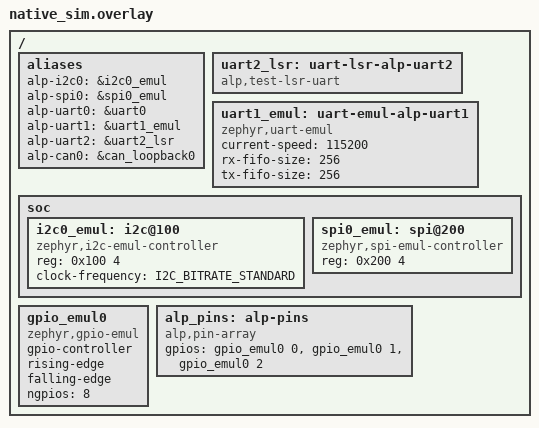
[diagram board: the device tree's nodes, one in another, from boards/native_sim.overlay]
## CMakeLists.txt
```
# SPDX-License-Identifier: Apache-2.0

cmake_minimum_required(VERSION 3.20)

find_package(Zephyr REQUIRED HINTS $ENV{ZEPHYR_BASE})
project(alp_sdk_peripheral_test LANGUAGES C)

# Per-peripheral split landed in §C.16.  main.c keeps the ZTEST_SUITE
# declaration plus the cross-cutting tests (TMU / power / AEN audit
# surfaces / delay / SoC caps / V2N supervisor / TRNG entropy); every
# *.c sibling here registers its ZTESTs against the same suite.
target_sources(app PRIVATE
    src/main.c
    src/config_defaults.c
    src/i2c.c
    src/i2c_target.c
    src/i3c.c
    src/spi.c
    src/spi_target.c
    src/gpio.c
    src/uart.c
    src/lsr_uart.c
    src/pwm.c
    src/adc.c
    src/dac.c
    src/counter.c
    src/qenc.c
    src/i2s.c
    src/can.c
    src/rtc.c
    src/wdt.c
    src/jpeg_bounds.c
)
```

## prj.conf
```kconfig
# SPDX-License-Identifier: Apache-2.0

CONFIG_ZTEST=y
CONFIG_ALP_SDK=y

# Zephyr subsystems we wrap
CONFIG_GPIO=y
CONFIG_I2C=y
CONFIG_SPI=y
CONFIG_SERIAL=y

# v0.2 peripheral subsystems — needed so the wrapper sources compile
# and the alp_*_open NULL/INVAL/last_error paths can be exercised.
# No corresponding controllers in the overlay; alp_*_open returns
# NULL with a precise last_error code.
CONFIG_ADC=y
CONFIG_PWM=y
CONFIG_COUNTER=y
CONFIG_SENSOR=y
CONFIG_I2S=y
CONFIG_CAN=y
CONFIG_RTC=y
CONFIG_WATCHDOG=y
# Required for thread-local last-error storage.
CONFIG_THREAD_LOCAL_STORAGE=y

# peripheral_i2s.c calls k_malloc to allocate its DMA slab; without
# a heap pool the linker rejects the reference.  4 KiB is enough
# for the test's open-with-NULL paths -- real apps that exercise
# alp_i2s_write set this higher.
CONFIG_HEAP_MEM_POOL_SIZE=4096

# Emulated controllers — let the test run under native_sim.
CONFIG_EMUL=y
CONFIG_GPIO_EMUL=y
CONFIG_I2C_EMUL=y
CONFIG_SPI_EMUL=y
# #626: alp-uart1 (RX byte injection for the timeout_ms contract tests
# in src/uart.c) is backed by zephyr,uart-emul, not a real controller.
CONFIG_UART_EMUL=y

CONFIG_LOG=y

# I2C target (slave) mode: compiles the emulated controller's
# target-register hooks so the alp_i2c_target_* lifecycle tests can
# run the open/close roundtrip (nothing external ever drives the
# emulated bus, so callbacks never fire).
CONFIG_I2C_TARGET=y

# SPI target (slave) mode: compiles the SPI drivers' slave path so
# alp_spi_target_open can claim the emulated bus.  CONFIG_SPI_ASYNC
# stays OFF here on purpose -- the spi_target tests pin down the
# documented degrade: a finite transceive timeout on a sync-only
# build must fail with ALP_ERR_NOSUPPORT instead of blocking.
CONFIG_SPI_SLAVE=y
```

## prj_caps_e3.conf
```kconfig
# SPDX-License-Identifier: Apache-2.0
#
# Overlay onto prj.conf for the alp_sdk.peripheral.caps_e3 scenario.
# Pins the SoC choice to Alif Ensemble E3 so the capability-validation
# tests in main.c can verify *_open rejects configs that exceed the
# E3's documented hardware caps.

CONFIG_ALP_SOC_ALIF_ENSEMBLE_E3=y
```

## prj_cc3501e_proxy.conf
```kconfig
# SPDX-License-Identifier: Apache-2.0
#
# Turns on the CC3501E GPIO proxy so src/gpio_proxy.c's delegated-path
# test (issue #1618) compiles and runs.  The proxy registers at priority
# 200, above the platform gpio backend's 100, so alp_gpio_open() goes
# through px_open here.  With the shipped weak-EMPTY cc3501e_gpio_routes[]
# table and no alp_gpio_cc3501e_attach() call, EVERY pin takes the
# delegated path -- which is the path under test.
#
# Kept out of prj.conf on purpose: enabling the proxy for every scenario
# in this directory would route every existing GPIO test through it.
CONFIG_ALP_SDK_CHIP_CC3501E=y
CONFIG_ALP_SDK_GPIO_CC3501E_PROXY=y
```

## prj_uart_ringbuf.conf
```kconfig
# SPDX-License-Identifier: Apache-2.0
# Twister overlay that flips CONFIG_ALP_SDK_UART_RX_RINGBUF on so the
# interrupt-driven RX ring buffer code path in peripheral_uart.c is
# compile-tested alongside its NOSUPPORT siblings.  Real-IRQ attach
# requires a working UART driver (HIL) so the failure-path tests
# here verify NULL-arg handling only.

CONFIG_UART_INTERRUPT_DRIVEN=y
CONFIG_ALP_SDK_UART_RX_RINGBUF=y
```

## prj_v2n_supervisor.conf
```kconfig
# SPDX-License-Identifier: Apache-2.0
#
# Overlay onto prj.conf for the alp_sdk.peripheral.v2n_supervisor
# scenario.  Force-enables the V2N SoC choice + GD32G553 chip driver
# + the supervisor singleton so the bridge dispatcher branches in
# peripheral_pwm.c / _adc.c / _qenc.c / _counter.c / _dac.c get
# compiled and the open() paths surface ALP_ERR_NOT_READY from the
# supervisor (no bus IDs configured -> no actual GD32 link).
#
# This scenario does NOT exercise the GD32 firmware -- native_sim
# has no SPI/I2C controller wired to a GD32 emul.  The intent is to
# prove that the V2N branch compiles + routes correctly back to the
# portable surface; real-silicon round-trip coverage lives in the
# v2n HIL test plan.

CONFIG_ALP_SOC_RENESAS_RZV2N_N44=y
CONFIG_ALP_SDK_CHIP_GD32G553=y
CONFIG_ALP_SDK_V2N_SUPERVISOR=y
# ALP_ADC_HAS_FILTER_PATH (src/zephyr/peripheral_adc.c) needs BOTH
# CONFIG_ALP_SDK_DSP and the V2N bridge path -- without this, the
# alp_adc_filter_*/alp_adc_spectrum_* bodies above are never compiled
# by any gate in the tree (issue #1634 dev-review follow-up).
CONFIG_ALP_SDK_DSP=y
```

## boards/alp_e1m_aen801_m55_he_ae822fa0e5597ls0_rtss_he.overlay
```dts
/*
 * Copyright 2026 Alp Lab AB
 * SPDX-License-Identifier: Apache-2.0
 *
 * Overlay for running the Alp SDK peripheral ztest on the
 * E1M EVK (UG-E1M-001) populated with an E1M-AEN family SoM.
 *
 * Wires the studio-resolved peripheral aliases to the EVK
 * connectors: I2C0 to the on-board sensor bus, SPI0 to the M.2
 * Key M slot, UART0 to the JTAG/SWD header's serial side, and the
 * alp,pin-array to the rotary encoder + RGB LED + IO-expander
 * control pins.
 *
 * The alp,pin-array is POSITIONAL: alp_z_gpio_resolve(pin_id)
 * indexes it by the E1M GPIO index, so entry N is E1M pad N in the
 * e1m_pinout.h canonical order (IO0..IO25 = 0..25, PWM0..PWM7 =
 * 26..33, ...).  The EVK's RGB LED sits on PWM pads, so it is
 * driven through the pads' GPIO-secondary indices (ALP_E1M_GPIO_PWM*);
 * this overlay covers indices 0..29.
 *
 * The alp_e1m_aen801_m55_he board file itself ships in-tree at
 * zephyr/boards/alp/e1m_aen801_m55_he/; this overlay only re-aliases
 * what that board exposes.
 */

#include <zephyr/dt-bindings/gpio/gpio.h>

/ {
    aliases {
        alp-i2c0  = &i2c0;       /* sensor bus on the EVK (ICM-42670-P, BMI323, BMP581, TCAL9538) */
        alp-spi0  = &spi0;       /* routed to the M.2 Key M slot for off-board flash */
        alp-uart0 = &uart0;      /* console / JTAG-side debug uart */
    };

    /* Positional alp,pin-array (e1m_pinout.h canonical order).  Only
     * the indices the EVK routes carry a meaningful net; the rest are
     * placeholders so the positional index stays stable.  The gpio
     * bank/pin numbers are PLACEHOLDERS (see NOTE below).  */
    alp_pins: alp-pins {
        compatible = "alp,pin-array";
        gpios = <&gpio0  0 GPIO_ACTIVE_HIGH>,                            /* [ 0] ALP_E1M_GPIO_IO0  (unrouted placeholder) */
                <&gpio0  1 GPIO_ACTIVE_HIGH>,                            /* [ 1] ALP_E1M_GPIO_IO1  (unrouted placeholder) */
                <&gpio0  2 GPIO_ACTIVE_HIGH>,                            /* [ 2] ALP_E1M_GPIO_IO2  (unrouted placeholder) */
                <&gpio0  3 GPIO_ACTIVE_HIGH>,                            /* [ 3] ALP_E1M_GPIO_IO3  (unrouted placeholder) */
                <&gpio1  0 (GPIO_ACTIVE_HIGH | GPIO_PULL_UP)>,           /* [ 4] ALP_E1M_GPIO_IO4  -- EVK_PIN_ENCODER_SW */
                <&gpio0  5 GPIO_ACTIVE_HIGH>,                            /* [ 5] ALP_E1M_GPIO_IO5  (unrouted placeholder) */
                <&gpio0  6 GPIO_ACTIVE_HIGH>,                            /* [ 6] ALP_E1M_GPIO_IO6  (unrouted placeholder) */
                <&gpio1  1 GPIO_ACTIVE_HIGH>,                            /* [ 7] ALP_E1M_GPIO_IO7  -- EVK_PIN_PCIE_IOEXP_INT */
                <&gpio0  8 GPIO_ACTIVE_HIGH>,                            /* [ 8] ALP_E1M_GPIO_IO8  (unrouted placeholder) */
                <&gpio1  2 GPIO_ACTIVE_HIGH>,                            /* [ 9] ALP_E1M_GPIO_IO9  -- EVK_PIN_PCIE_IOEXP_RST */
                <&gpio0 10 GPIO_ACTIVE_HIGH>,                            /* [10] ALP_E1M_GPIO_IO10 (unrouted placeholder) */
                <&gpio0 11 GPIO_ACTIVE_HIGH>,                            /* [11] ALP_E1M_GPIO_IO11 (unrouted placeholder) */
                <&gpio0 12 GPIO_ACTIVE_HIGH>,                            /* [12] ALP_E1M_GPIO_IO12 (unrouted placeholder) */
                <&gpio0 13 GPIO_ACTIVE_HIGH>,                            /* [13] ALP_E1M_GPIO_IO13 (unrouted placeholder) */
                <&gpio0 14 GPIO_ACTIVE_HIGH>,                            /* [14] ALP_E1M_GPIO_IO14 (unrouted placeholder) */
                <&gpio0 15 GPIO_ACTIVE_HIGH>,                            /* [15] ALP_E1M_GPIO_IO15 (unrouted placeholder) */
                <&gpio0 16 GPIO_ACTIVE_HIGH>,                            /* [16] ALP_E1M_GPIO_IO16 (unrouted placeholder) */
                <&gpio0 17 GPIO_ACTIVE_HIGH>,                            /* [17] ALP_E1M_GPIO_IO17 (unrouted placeholder) */
                <&gpio0 18 GPIO_ACTIVE_HIGH>,                            /* [18] ALP_E1M_GPIO_IO18 (unrouted placeholder) */
                <&gpio0 19 GPIO_ACTIVE_HIGH>,                            /* [19] ALP_E1M_GPIO_IO19 (unrouted placeholder) */
                <&gpio0 20 GPIO_ACTIVE_HIGH>,                            /* [20] ALP_E1M_GPIO_IO20 (unrouted placeholder) */
                <&gpio0 21 GPIO_ACTIVE_HIGH>,                            /* [21] ALP_E1M_GPIO_IO21 (unrouted placeholder) */
                <&gpio0 22 GPIO_ACTIVE_HIGH>,                            /* [22] ALP_E1M_GPIO_IO22 (unrouted placeholder) */
                <&gpio0 23 GPIO_ACTIVE_HIGH>,                            /* [23] ALP_E1M_GPIO_IO23 (unrouted placeholder) */
                <&gpio0 24 GPIO_ACTIVE_HIGH>,                            /* [24] ALP_E1M_GPIO_IO24 (unrouted placeholder) */
                <&gpio0 25 GPIO_ACTIVE_HIGH>,                            /* [25] ALP_E1M_GPIO_IO25 (unrouted placeholder) */
                <&gpio0 26 GPIO_ACTIVE_HIGH>,                            /* [26] ALP_E1M_GPIO_PWM0 -- EVK_PWM_LED_GREEN as GPIO */
                <&gpio0 27 GPIO_ACTIVE_HIGH>,                            /* [27] ALP_E1M_GPIO_PWM1 -- EVK_PWM_LED_BLUE as GPIO */
                <&gpio0 28 GPIO_ACTIVE_HIGH>,                            /* [28] ALP_E1M_GPIO_PWM2 (unrouted placeholder) */
                <&gpio0 29 GPIO_ACTIVE_HIGH>;                            /* [29] ALP_E1M_GPIO_PWM3 -- EVK_PWM_LED_RED as GPIO */
    };
};

/*
 * NOTE — gpio bank/pin numbers in the gpios property above are
 * PLACEHOLDERS.  The authoritative mapping lands when the
 * alp_e1m_aen801_m55_he board file (zephyr/boards/alp/e1m_aen801_m55_he/)
 * grows a pinctrl group naming the exact gpio bank/index for each
 * EVK net (RGB LED on the PWM pads, encoder switch, IO_EXP.INT/RST).
 * The POSITIONAL INDEX (the [NN] in each comment) is the stable ABI;
 * only the <&gpioX Y> columns are TBD.
 */
```

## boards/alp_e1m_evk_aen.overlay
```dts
/*
 * Copyright 2026 Alp Lab AB
 * SPDX-License-Identifier: Apache-2.0
 *
 * Overlay for running the Alp SDK peripheral ztest on the
 * E1M EVK (UG-E1M-001) populated with an E1M-AEN family SoM.
 *
 * Wires the studio-resolved peripheral aliases to the EVK
 * connectors: I2C0 to the on-board sensor bus, SPI0 to the M.2
 * Key M slot, UART0 to the JTAG/SWD header's serial side, and the
 * alp,pin-array to the rotary encoder + RGB LED + IO-expander
 * control pins.
 *
 * The alp,pin-array is POSITIONAL: alp_z_gpio_resolve(pin_id)
 * indexes it by the E1M GPIO index, so entry N is E1M pad N in the
 * e1m_pinout.h canonical order (IO0..IO25 = 0..25, PWM0..PWM7 =
 * 26..33, ...).  The EVK's RGB LED sits on PWM pads, so it is
 * driven through the pads' GPIO-secondary indices (ALP_E1M_GPIO_PWM*);
 * this overlay covers indices 0..29.
 *
 * The alp_e1m_evk_aen board file itself lives in
 * alplabai/alp-zephyr-modules; this overlay only re-aliases what
 * that board exposes.
 */

#include <zephyr/dt-bindings/gpio/gpio.h>

/ {
    aliases {
        alp-i2c0  = &i2c0;       /* sensor bus on the EVK (ICM-42670-P, BMI323, BMP581, TCAL9538) */
        alp-spi0  = &spi0;       /* routed to the M.2 Key M slot for off-board flash */
        alp-uart0 = &uart0;      /* console / JTAG-side debug uart */
    };

    /* Positional alp,pin-array (e1m_pinout.h canonical order).  Only
     * the indices the EVK routes carry a meaningful net; the rest are
     * placeholders so the positional index stays stable.  The gpio
     * bank/pin numbers are PLACEHOLDERS (see NOTE below).  */
    alp_pins: alp-pins {
        compatible = "alp,pin-array";
        gpios = <&gpio0  0 GPIO_ACTIVE_HIGH>,                            /* [ 0] ALP_E1M_GPIO_IO0  (unrouted placeholder) */
                <&gpio0  1 GPIO_ACTIVE_HIGH>,                            /* [ 1] ALP_E1M_GPIO_IO1  (unrouted placeholder) */
                <&gpio0  2 GPIO_ACTIVE_HIGH>,                            /* [ 2] ALP_E1M_GPIO_IO2  (unrouted placeholder) */
                <&gpio0  3 GPIO_ACTIVE_HIGH>,                            /* [ 3] ALP_E1M_GPIO_IO3  (unrouted placeholder) */
                <&gpio1  0 (GPIO_ACTIVE_HIGH | GPIO_PULL_UP)>,           /* [ 4] ALP_E1M_GPIO_IO4  -- EVK_PIN_ENCODER_SW */
                <&gpio0  5 GPIO_ACTIVE_HIGH>,                            /* [ 5] ALP_E1M_GPIO_IO5  (unrouted placeholder) */
                <&gpio0  6 GPIO_ACTIVE_HIGH>,                            /* [ 6] ALP_E1M_GPIO_IO6  (unrouted placeholder) */
                <&gpio1  1 GPIO_ACTIVE_HIGH>,                            /* [ 7] ALP_E1M_GPIO_IO7  -- EVK_PIN_PCIE_IOEXP_INT */
                <&gpio0  8 GPIO_ACTIVE_HIGH>,                            /* [ 8] ALP_E1M_GPIO_IO8  (unrouted placeholder) */
                <&gpio1  2 GPIO_ACTIVE_HIGH>,                            /* [ 9] ALP_E1M_GPIO_IO9  -- EVK_PIN_PCIE_IOEXP_RST */
                <&gpio0 10 GPIO_ACTIVE_HIGH>,                            /* [10] ALP_E1M_GPIO_IO10 (unrouted placeholder) */
                <&gpio0 11 GPIO_ACTIVE_HIGH>,                            /* [11] ALP_E1M_GPIO_IO11 (unrouted placeholder) */
                <&gpio0 12 GPIO_ACTIVE_HIGH>,                            /* [12] ALP_E1M_GPIO_IO12 (unrouted placeholder) */
                <&gpio0 13 GPIO_ACTIVE_HIGH>,                            /* [13] ALP_E1M_GPIO_IO13 (unrouted placeholder) */
                <&gpio0 14 GPIO_ACTIVE_HIGH>,                            /* [14] ALP_E1M_GPIO_IO14 (unrouted placeholder) */
                <&gpio0 15 GPIO_ACTIVE_HIGH>,                            /* [15] ALP_E1M_GPIO_IO15 (unrouted placeholder) */
                <&gpio0 16 GPIO_ACTIVE_HIGH>,                            /* [16] ALP_E1M_GPIO_IO16 (unrouted placeholder) */
                <&gpio0 17 GPIO_ACTIVE_HIGH>,                            /* [17] ALP_E1M_GPIO_IO17 (unrouted placeholder) */
                <&gpio0 18 GPIO_ACTIVE_HIGH>,                            /* [18] ALP_E1M_GPIO_IO18 (unrouted placeholder) */
                <&gpio0 19 GPIO_ACTIVE_HIGH>,                            /* [19] ALP_E1M_GPIO_IO19 (unrouted placeholder) */
                <&gpio0 20 GPIO_ACTIVE_HIGH>,                            /* [20] ALP_E1M_GPIO_IO20 (unrouted placeholder) */
                <&gpio0 21 GPIO_ACTIVE_HIGH>,                            /* [21] ALP_E1M_GPIO_IO21 (unrouted placeholder) */
                <&gpio0 22 GPIO_ACTIVE_HIGH>,                            /* [22] ALP_E1M_GPIO_IO22 (unrouted placeholder) */
                <&gpio0 23 GPIO_ACTIVE_HIGH>,                            /* [23] ALP_E1M_GPIO_IO23 (unrouted placeholder) */
                <&gpio0 24 GPIO_ACTIVE_HIGH>,                            /* [24] ALP_E1M_GPIO_IO24 (unrouted placeholder) */
                <&gpio0 25 GPIO_ACTIVE_HIGH>,                            /* [25] ALP_E1M_GPIO_IO25 (unrouted placeholder) */
                <&gpio0 26 GPIO_ACTIVE_HIGH>,                            /* [26] ALP_E1M_GPIO_PWM0 -- EVK_PWM_LED_GREEN as GPIO */
                <&gpio0 27 GPIO_ACTIVE_HIGH>,                            /* [27] ALP_E1M_GPIO_PWM1 -- EVK_PWM_LED_BLUE as GPIO */
                <&gpio0 28 GPIO_ACTIVE_HIGH>,                            /* [28] ALP_E1M_GPIO_PWM2 (unrouted placeholder) */
                <&gpio0 29 GPIO_ACTIVE_HIGH>;                            /* [29] ALP_E1M_GPIO_PWM3 -- EVK_PWM_LED_RED as GPIO */
    };
};

/*
 * NOTE — gpio bank/pin numbers in the gpios property above are
 * PLACEHOLDERS.  The authoritative mapping lands when
 * alplabai/alp-zephyr-modules publishes the alp_e1m_evk_aen board
 * file with a pinctrl group naming the exact gpio bank/index for each
 * EVK net (RGB LED on the PWM pads, encoder switch, IO_EXP.INT/RST).
 * The POSITIONAL INDEX (the [NN] in each comment) is the stable ABI;
 * only the <&gpioX Y> columns are TBD.
 */
```

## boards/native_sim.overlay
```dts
/*
 * Copyright 2026 Alp Lab AB
 * SPDX-License-Identifier: Apache-2.0
 *
 * Devicetree overlay for the alp-sdk peripheral ztest under
 * native_sim.  Wires three emulated GPIOs, one emulated I2C bus,
 * one emulated SPI bus, the existing native_sim UART (uart0), and
 * one emulated UART (uart-emul) to the alias names alp_sdk's Zephyr
 * backend looks up.
 */

#include <zephyr/dt-bindings/gpio/gpio.h>

/ {
    aliases {
        alp-i2c0  = &i2c0_emul;
        alp-spi0  = &spi0_emul;
        alp-uart0 = &uart0;
        alp-uart1 = &uart1_emul;
        alp-uart2 = &uart2_lsr;
        /* #1631: alp-can0 -> the board's own can_loopback0 (status
         * "okay" by default in native_sim.dts) so the CAN backend's
         * z_send() bound-check test in
         * tests/zephyr/peripheral/src/can.c opens a REAL Zephyr CAN
         * device instead of the NULL that ALP_CAN_DEV_OR_NULL()
         * yields (src/backends/can/zephyr_drv.c) when the alias is
         * unset. */
        alp-can0  = &can_loopback0;
    };

    /* #626: alp_uart_read()'s timeout_ms == 0 / finite / partial-fill
     * contract needs bytes we control injecting into RX -- uart0 is
     * native_sim's real backing UART with no test-side RX hook, so a
     * second, purely emulated UART (uart_emul_put_rx_data()) backs
     * the timeout tests in src/uart.c instead of port 0. */
    /* #2934: UART whose poll_in() clears the error latch like ns16550's LSR
     * read (src/lsr_uart.c). */
    uart2_lsr: uart-lsr-alp-uart2 {
        compatible = "alp,test-lsr-uart";
        status = "okay";
    };

    uart1_emul: uart-emul-alp-uart1 {
        compatible = "zephyr,uart-emul";
        status = "okay";
        current-speed = <115200>;
        rx-fifo-size = <256>;
        tx-fifo-size = <256>;
    };

    soc {
        i2c0_emul: i2c@100 {
            compatible = "zephyr,i2c-emul-controller";
            status = "okay";
            reg = <0x100 4>;
            #address-cells = <1>;
            #size-cells = <0>;
            clock-frequency = <I2C_BITRATE_STANDARD>;
        };

        spi0_emul: spi@200 {
            compatible = "zephyr,spi-emul-controller";
            status = "okay";
            reg = <0x200 4>;
            #address-cells = <1>;
            #size-cells = <0>;
        };
    };

    gpio_emul0: gpio_emul0 {
        compatible = "zephyr,gpio-emul";
        status = "okay";
        gpio-controller;
        rising-edge;
        falling-edge;
        #gpio-cells = <2>;
        ngpios = <8>;
    };

    alp_pins: alp-pins {
        compatible = "alp,pin-array";
        gpios = <&gpio_emul0 0 GPIO_ACTIVE_HIGH>,
                <&gpio_emul0 1 GPIO_ACTIVE_HIGH>,
                <&gpio_emul0 2 (GPIO_ACTIVE_HIGH | GPIO_PULL_UP)>;
    };
};
```

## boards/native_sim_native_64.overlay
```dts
/*
 * Copyright 2026 Alp Lab AB
 * SPDX-License-Identifier: Apache-2.0
 *
 * Devicetree overlay for the alp-sdk peripheral ztest under
 * native_sim.  Wires three emulated GPIOs, one emulated I2C bus,
 * one emulated SPI bus, the existing native_sim UART (uart0), and
 * one emulated UART (uart-emul) to the alias names alp_sdk's Zephyr
 * backend looks up.
 */

#include <zephyr/dt-bindings/gpio/gpio.h>
#include <zephyr/dt-bindings/i2c/i2c.h>

/ {
    aliases {
        alp-i2c0  = &i2c0_emul;
        alp-spi0  = &spi0_emul;
        alp-uart0 = &uart0;
        alp-uart1 = &uart1_emul;
        alp-uart2 = &uart2_lsr;
        /* #1631: alp-can0 -> the board's own can_loopback0 (status
         * "okay" by default in native_sim.dts, #include-d by this
         * platform's own native_sim_64.dts) so the CAN backend's
         * z_send() bound-check test in
         * tests/zephyr/peripheral/src/can.c opens a REAL Zephyr CAN
         * device instead of the NULL that ALP_CAN_DEV_OR_NULL()
         * yields (src/backends/can/zephyr_drv.c) when the alias is
         * unset. */
        alp-can0  = &can_loopback0;
    };

    /* #626: alp_uart_read()'s timeout_ms == 0 / finite / partial-fill
     * contract needs bytes we control injecting into RX -- uart0 is
     * native_sim's real backing UART with no test-side RX hook, so a
     * second, purely emulated UART (uart_emul_put_rx_data()) backs
     * the timeout tests in src/uart.c instead of port 0. */
    /* #2934: UART whose poll_in() clears the error latch like ns16550's LSR
     * read (src/lsr_uart.c). */
    uart2_lsr: uart-lsr-alp-uart2 {
        compatible = "alp,test-lsr-uart";
        status = "okay";
    };

    uart1_emul: uart-emul-alp-uart1 {
        compatible = "zephyr,uart-emul";
        status = "okay";
        current-speed = <115200>;
        rx-fifo-size = <256>;
        tx-fifo-size = <256>;
    };

    /* native_sim's /soc has #address-cells=2, #size-cells=1, so
     * `reg` needs three cells: <addr_hi addr_lo size>. */
    soc {
        i2c0_emul: i2c@100 {
            compatible = "zephyr,i2c-emul-controller";
            status = "okay";
            reg = <0 0x100 4>;
            #address-cells = <1>;
            #size-cells = <0>;
            clock-frequency = <I2C_BITRATE_STANDARD>;
        };

        spi0_emul: spi@200 {
            compatible = "zephyr,spi-emul-controller";
            status = "okay";
            reg = <0 0x200 4>;
            #address-cells = <1>;
            #size-cells = <0>;
        };
    };

    gpio_emul0: gpio_emul0 {
        compatible = "zephyr,gpio-emul";
        status = "okay";
        gpio-controller;
        rising-edge;
        falling-edge;
        #gpio-cells = <2>;
        ngpios = <8>;
    };

    alp_pins: alp-pins {
        compatible = "alp,pin-array";
        gpios = <&gpio_emul0 0 GPIO_ACTIVE_HIGH>,
                <&gpio_emul0 1 GPIO_ACTIVE_HIGH>,
                <&gpio_emul0 2 (GPIO_ACTIVE_HIGH | GPIO_PULL_UP)>;
    };
};
```

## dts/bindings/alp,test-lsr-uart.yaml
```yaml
# SPDX-License-Identifier: Apache-2.0
description: |
  Test-only UART whose poll_in() clears the error latch the way ns16550's LSR
  read does (see src/lsr_uart.c).  Not a real controller.

compatible: "alp,test-lsr-uart"

include: base.yaml
```

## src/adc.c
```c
/*
 * Copyright 2026 Alp Lab AB
 * SPDX-License-Identifier: Apache-2.0
 *
 * <alp/adc.h> -- ADC wrapper tests.  Extracted from main.c in §C.16.
 * Covers the basic open NULL+OOB paths and the streaming ADC surface
 * (alp_adc_stream_*).  Default native_sim builds have no streaming
 * backend so streaming open returns NOSUPPORT for valid configs --
 * the NULL-cfg path stays INVAL on every backend.
 */

#include <zephyr/ztest.h>

#include "alp/adc.h"
#include "alp/peripheral.h"

ZTEST(alp_peripheral, test_adc_null_cfg)
{
	zassert_is_null(alp_adc_open(NULL));
	zassert_equal(alp_last_error(), ALP_ERR_INVAL);
}

ZTEST(alp_peripheral, test_adc_unresolved_channel_yields_not_ready)
{
	/* channel_id=0 is in-range; with no `alp-adc0` alias on this
     * test's overlay the spec is NULL → ALP_ERR_NOT_READY. */
	alp_adc_t *a = alp_adc_open(&(alp_adc_config_t){ .channel_id = 0, .resolution_bits = 12 });
	zassert_is_null(a);
#if defined(CONFIG_ALP_SOC_NONE)
	/* With no SoC selected, capability checks pass through and we
     * land on the device-not-ready path. */
	zassert_equal(alp_last_error(), ALP_ERR_NOT_READY);
#endif
}

/* ------------------------------------------------------------------ */
/* Streaming ADC                                                       */
/*                                                                     */
/* Default native_sim builds have no streaming backend (the Zephyr     */
/* adc_* class doesn't expose a portable streaming primitive matching  */
/* alp_adc_stream_*), so open() returns NULL + ALP_ERR_NOSUPPORT for   */
/* any non-NULL config.  The NULL-cfg path returns INVAL regardless,   */
/* and the read/close NULL-arg paths must always be safe.              */
/* ------------------------------------------------------------------ */

ZTEST(alp_peripheral, test_adc_stream_null_cfg)
{
	zassert_is_null(alp_adc_stream_open(NULL));
	zassert_equal(alp_last_error(), ALP_ERR_INVAL);
}

ZTEST(alp_peripheral, test_adc_stream_read_null_handle_yields_not_ready)
{
	uint16_t     buf[4];
	size_t       got = 99u;
	alp_status_t s   = alp_adc_stream_read_mv(NULL, buf, ARRAY_SIZE(buf), &got);
	zassert_equal(s, ALP_ERR_NOT_READY, "got %d", (int)s);
	zassert_equal(got, 0u, "got must be zeroed on failure");
}

ZTEST(alp_peripheral, test_adc_stream_read_null_got_is_inval)
{
	uint16_t     buf[4];
	alp_status_t s = alp_adc_stream_read_mv(NULL, buf, ARRAY_SIZE(buf), NULL);
	zassert_equal(s, ALP_ERR_INVAL, "NULL got pointer must be INVAL, got %d", (int)s);
}

ZTEST(alp_peripheral, test_adc_stream_close_null_safe)
{
	/* Must not crash. */
	alp_adc_stream_close(NULL);
}

#if !defined(CONFIG_ALP_SDK_V2N_SUPERVISOR)
ZTEST(alp_peripheral, test_adc_stream_open_no_backend_yields_nosupport)
{
	/* Default build has no streaming backend.  Any well-formed cfg
     * lands on the NOSUPPORT sentinel; this catches accidental
     * regressions where a future backend silently links in. */
	alp_adc_stream_t *s = alp_adc_stream_open(&(alp_adc_stream_config_t){
	    .channel_id     = 0u,
	    .sample_rate_hz = 100000u,
	});
	zassert_is_null(s);
	zassert_equal(alp_last_error(), ALP_ERR_NOSUPPORT);
}
#endif
```

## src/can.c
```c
/*
 * Copyright 2026 Alp Lab AB
 * SPDX-License-Identifier: Apache-2.0
 *
 * <alp/can.h> -- CAN wrapper tests.  Extracted from main.c in §C.16.
 */

#include <string.h>

#include <zephyr/ztest.h>

#include "alp/can.h"
#include "alp/peripheral.h"

ZTEST(alp_peripheral, test_can_null_cfg)
{
	zassert_is_null(alp_can_open(NULL));
	zassert_equal(alp_last_error(), ALP_ERR_INVAL);
}

ZTEST(alp_peripheral, test_can_zero_bitrate_rejected)
{
	alp_can_t *c = alp_can_open(&(alp_can_config_t){ .bus_id             = 0,
	                                                 .bitrate_nominal_hz = 0, /* INVAL */
	                                                 .mode               = ALP_CAN_MODE_CLASSIC });
	zassert_is_null(c);
	zassert_equal(alp_last_error(), ALP_ERR_INVAL);
}

/* #1631: an fd-flagged, 64-byte frame sent on a handle opened
 * ALP_CAN_MODE_CLASSIC must be rejected cleanly -- src/can_dispatch.c's
 * payload_len bound check alone lets it through (64 is not
 * > ALP_CAN_MAX_PAYLOAD_BYTES_FD, and the classic-payload arm is
 * skipped because frame->fd is true), so without the mode guard this
 * reaches src/backends/can/zephyr_drv.c's z_send(), which memcpy()s
 * frame->payload_len bytes into an on-stack struct can_frame sized by
 * Zephyr's CAN_MAX_DLEN -- 8 bytes on this suite's build (no
 * CONFIG_CAN_FD_MODE) -- a 56-byte stack overflow. */
ZTEST(alp_peripheral, test_can_fd_frame_rejected_on_classic_handle)
{
	alp_can_t *c = alp_can_open(&(alp_can_config_t){
	    .bus_id = 0, .bitrate_nominal_hz = 500000, .mode = ALP_CAN_MODE_CLASSIC });
	zassert_not_null(c, "alp_can_open(0) returned NULL -- is native_sim's alp-can0 alias wired?");
	zassert_equal(alp_can_start(c), ALP_OK, "alp_can_start() failed");

	alp_can_frame_t frame = { 0 };
	frame.id              = 0x123;
	frame.fd              = true;
	frame.payload_len     = ALP_CAN_MAX_PAYLOAD_BYTES_FD; /* 64 */
	memset(frame.data, 0x5A, sizeof(frame.data));

	alp_status_t rc = alp_can_send(c, &frame, 100);
	zassert_equal(rc,
	              ALP_ERR_NOSUPPORT,
	              "fd-flagged 64-byte send on a classic-mode handle returned %d, not "
	              "ALP_ERR_NOSUPPORT from src/can_dispatch.c's mode guard",
	              (int)rc);

	alp_can_close(c);
}
```

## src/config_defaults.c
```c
/*
 * Copyright 2026 Alp Lab AB
 * SPDX-License-Identifier: Apache-2.0
 *
 * ALP_*_CONFIG_DEFAULT(id) contract (#610 WS1): each macro fills the
 * identity field from its argument and every other field with the one
 * canonical default documented in the public header. These tests pin
 * those defaults so a header edit that silently changes a default is
 * caught. They assert VALUES, not hardware behavior -- the macros are
 * header-only, so this runs on native_sim with no backend.
 */

#include <zephyr/ztest.h>

#include "alp/peripheral.h"
#include "alp/pwm.h"
#include "alp/dac.h"
#include "alp/wdt.h"
#include "alp/counter.h"
#include "alp/can.h"
#include "alp/adc.h"
#include "alp/audio.h"
#include "alp/ble.h"
#include "alp/camera.h"
#include "alp/display.h"
#include "alp/i2s.h"
#include "alp/inference.h"
#include "alp/mproc.h"
#include "alp/iot.h"
#include "alp/rpc.h"
#include "alp/storage.h"
#include "alp/usb.h"

ZTEST(alp_peripheral, test_i2c_config_default)
{
	alp_i2c_config_t cfg = ALP_I2C_CONFIG_DEFAULT(5u);
	zassert_equal(cfg.bus_id, 5u, "identity from the macro arg");
	zassert_equal(cfg.bitrate_hz, 100000u, "I2C standard-mode default");
}

ZTEST(alp_peripheral, test_spi_config_default)
{
	alp_spi_config_t cfg = ALP_SPI_CONFIG_DEFAULT(2u);
	zassert_equal(cfg.bus_id, 2u, NULL);
	zassert_equal(cfg.freq_hz, 1000000u, "1 MHz default");
	zassert_equal(cfg.mode, ALP_SPI_MODE_0, "mode 0 default");
	zassert_equal(cfg.bits_per_word, 8u, NULL);
	zassert_equal(cfg.cs_pin_id, ALP_SPI_NO_CS, "no controller-driven CS by default");
}

ZTEST(alp_peripheral, test_uart_config_default)
{
	alp_uart_config_t cfg = ALP_UART_CONFIG_DEFAULT(3u);
	zassert_equal(cfg.port_id, 3u, NULL);
	zassert_equal(cfg.baudrate, 115200u, "115200 8N1");
	zassert_equal(cfg.data_bits, 8u, NULL);
	zassert_equal(cfg.stop_bits, 1u, NULL);
	zassert_equal(cfg.parity, ALP_UART_PARITY_NONE, NULL);
	zassert_equal(cfg.flow_control, ALP_UART_FLOW_NONE, "no flow control by default");
}

ZTEST(alp_peripheral, test_pwm_config_default)
{
	alp_pwm_config_t cfg = ALP_PWM_CONFIG_DEFAULT(7u);
	zassert_equal(cfg.channel_id, 7u, NULL);
	zassert_equal(cfg.period_ns, 0u, "0 = devicetree default period");
	zassert_equal(cfg.polarity, ALP_PWM_POLARITY_NORMAL, NULL);
}

ZTEST(alp_peripheral, test_dac_config_default)
{
	alp_dac_config_t cfg = ALP_DAC_CONFIG_DEFAULT(1u);
	zassert_equal(cfg.channel_id, 1u, NULL);
	zassert_equal(cfg.initial_mv, 0u, "starts at ground");
}

ZTEST(alp_peripheral, test_wdt_config_default)
{
	alp_wdt_config_t cfg = ALP_WDT_CONFIG_DEFAULT(0u);
	zassert_equal(cfg.wdt_id, 0u, NULL);
	zassert_equal(cfg.timeout_ms, 1000u, "non-zero deadline (zero-init is invalid for wdt)");
	zassert_equal(cfg.on_timeout, ALP_WDT_RESET_SOC, "safest action default");
	/* #1637: on_expire/user are new fields the macro doesn't name --
     * the compound literal's designated initializers zero them, which
     * is correct because the default action is RESET_SOC, not
     * INTERRUPT_ONLY, so no callback is required. */
	zassert_is_null(cfg.on_expire, "unnamed fields zero-init");
	zassert_is_null(cfg.user, "unnamed fields zero-init");
}

ZTEST(alp_peripheral, test_counter_config_default)
{
	alp_counter_config_t cfg = ALP_COUNTER_CONFIG_DEFAULT(2u);
	zassert_equal(cfg.counter_id, 2u, "identity-only config");
}

ZTEST(alp_peripheral, test_can_config_default)
{
	alp_can_config_t cfg = ALP_CAN_CONFIG_DEFAULT(4u);
	zassert_equal(cfg.bus_id, 4u, NULL);
	zassert_equal(cfg.bitrate_nominal_hz, 500000u, "500k classic default");
	zassert_equal(cfg.bitrate_data_hz, 0u, "classic = no data-phase rate");
	zassert_equal(cfg.mode, ALP_CAN_MODE_CLASSIC, NULL);
	zassert_false(cfg.loopback, "on the wire, not local self-test");
}

/* -------------------------------------------------------------------- */
/* #610 WS2: remaining peripheral/subsystem configs                     */
/* -------------------------------------------------------------------- */

ZTEST(alp_peripheral, test_adc_config_default)
{
	alp_adc_config_t cfg = ALP_ADC_CONFIG_DEFAULT(6u);
	zassert_equal(cfg.channel_id, 6u, NULL);
	zassert_equal(cfg.resolution_bits, 0u, "0 = use DT default");
	zassert_equal(cfg.acquisition_us, 0u, "0 = use backend default");
	zassert_equal(cfg.reference, ALP_ADC_REF_INTERNAL, "on-die bandgap default");
	zassert_equal(cfg.gain_num, 1u, "unity gain 1/1");
	zassert_equal(cfg.gain_den, 1u, "unity gain 1/1");
	zassert_equal(cfg.oversampling_ratio, 0u, "0 = backend default");
	zassert_equal(cfg.sample_cycles, 0u, "0 = backend default");
}

ZTEST(alp_peripheral, test_adc_stream_config_default)
{
	alp_adc_stream_config_t cfg = ALP_ADC_STREAM_CONFIG_DEFAULT(1u);
	zassert_equal(cfg.channel_id, 1u, NULL);
	zassert_equal(cfg.sample_rate_hz, 0u, "0 sentinel -- caller MUST set before open()");
}

ZTEST(alp_peripheral, test_adc_filter_config_default)
{
	alp_adc_filter_config_t cfg = ALP_ADC_FILTER_CONFIG_DEFAULT(2u);
	zassert_equal(cfg.channel_id, 2u, NULL);
	zassert_equal(cfg.sample_rate_hz, 0u, "sentinel -- caller MUST set");
	zassert_is_null(cfg.stages, "sentinel -- caller MUST set the DSP chain");
	zassert_equal(cfg.n_stages, 0u, "sentinel -- caller MUST set");
}

ZTEST(alp_peripheral, test_adc_spectrum_config_default)
{
	alp_adc_spectrum_config_t cfg = ALP_ADC_SPECTRUM_CONFIG_DEFAULT(3u);
	zassert_equal(cfg.channel_id, 3u, NULL);
	zassert_equal(cfg.sample_rate_hz, 0u, "sentinel -- caller MUST set");
	zassert_is_null(cfg.stages, "sentinel -- caller MUST set the DSP chain");
	zassert_equal(cfg.n_stages, 0u, "sentinel -- caller MUST set");
}

ZTEST(alp_peripheral, test_audio_config_default)
{
	alp_audio_config_t cfg = ALP_AUDIO_CONFIG_DEFAULT(0u);
	zassert_equal(cfg.peripheral_id, 0u, NULL);
	zassert_equal(cfg.sample_rate_hz, 16000u, "16 kHz voice-band default");
	zassert_equal(cfg.channels, 1u, "mono default");
	zassert_equal(cfg.format, ALP_AUDIO_FMT_S16_LE, NULL);
	zassert_equal(cfg.frames_per_block, 256u, NULL);
}

ZTEST(alp_peripheral, test_ble_adv_config_default)
{
	alp_ble_adv_config_t cfg = ALP_BLE_ADV_CONFIG_DEFAULT("MyDevice");
	zassert_str_equal(cfg.name, "MyDevice", NULL);
	zassert_is_null(cfg.services, "no service UUIDs by default");
	zassert_equal(cfg.num_services, 0u, NULL);
	zassert_equal(cfg.interval_min_ms, 100u, NULL);
	zassert_equal(cfg.interval_max_ms, 200u, NULL);
	zassert_true(cfg.connectable, NULL);
}

ZTEST(alp_peripheral, test_camera_config_default)
{
	alp_camera_config_t cfg = ALP_CAMERA_CONFIG_DEFAULT(0u);
	zassert_equal(cfg.camera_id, 0u, NULL);
	zassert_equal(cfg.width, 0u, "sentinel -- caller MUST set a resolution");
	zassert_equal(cfg.height, 0u, "sentinel -- caller MUST set a resolution");
	zassert_equal(cfg.fps, 0u, "0 = let the backend pick its own default (#2278)");
	zassert_equal(cfg.format, ALP_PIXFMT_RGB565, "widely-supported embedded default");
}

ZTEST(alp_peripheral, test_display_config_default)
{
	alp_display_config_t cfg = ALP_DISPLAY_CONFIG_DEFAULT(2u);
	zassert_equal(cfg.display_id, 2u, "names the instance");
	/* The safe default, and the only thing pinning it.  On Yocto/Linux,
	 * opening a display means becoming DRM master and reprogramming the
	 * live output -- which the kernel permits whenever master is merely
	 * unheld (idle fbcon, VT-switched-away session, headless SSH on a
	 * board with a panel).  If this flips to true, a default-constructed
	 * config can blank someone's screen and nothing else would notice
	 * (#1143). */
	zassert_false(cfg.allow_modeset, "safe default -- see <alp/display.h>");
}

ZTEST(alp_peripheral, test_i2c_target_config_default)
{
	alp_i2c_target_config_t cfg = ALP_I2C_TARGET_CONFIG_DEFAULT(5u);
	zassert_equal(cfg.bus_id, 5u, NULL);
	zassert_equal(cfg.own_addr_7bit, 0u, "sentinel in the reserved range -- caller MUST set");
	zassert_is_null(cfg.on_write, "sentinel -- caller MUST set");
	zassert_is_null(cfg.on_read, "sentinel -- caller MUST set");
	zassert_is_null(cfg.on_stop, "optional");
	zassert_is_null(cfg.user, "optional");
}

ZTEST(alp_peripheral, test_spi_target_config_default)
{
	alp_spi_target_config_t cfg = ALP_SPI_TARGET_CONFIG_DEFAULT(2u);
	zassert_equal(cfg.bus_id, 2u, NULL);
	zassert_equal(cfg.mode, ALP_SPI_MODE_0, NULL);
	zassert_equal(cfg.bits_per_word, 0u, "0 = defaults to 8 per the backend");
}

ZTEST(alp_peripheral, test_i2s_config_default)
{
	alp_i2s_config_t cfg = ALP_I2S_CONFIG_DEFAULT(1u);
	zassert_equal(cfg.bus_id, 1u, NULL);
	zassert_equal(cfg.sample_rate_hz, 48000u, NULL);
	zassert_equal(cfg.word_bits, 16u, NULL);
	zassert_equal(cfg.channels, 2u, "stereo default");
	zassert_equal(cfg.format, ALP_I2S_FMT_I2S, "most modern codecs accept this");
	zassert_equal(cfg.direction, ALP_I2S_DIR_RX, "passive, listen-only default");
	zassert_equal(cfg.block_frames, 256u, NULL);
}

ZTEST(alp_peripheral, test_inference_config_default)
{
	static const uint8_t   dummy_model[4];
	alp_inference_config_t cfg = ALP_INFERENCE_CONFIG_DEFAULT(dummy_model);
	zassert_equal_ptr(cfg.model_data, dummy_model, NULL);
	zassert_equal(cfg.model_size, 0u, "sentinel -- caller MUST set");
	zassert_equal(cfg.format, ALP_INFERENCE_MODEL_TFLITE, NULL);
	zassert_equal(cfg.backend, ALP_INFERENCE_BACKEND_AUTO, NULL);
	zassert_equal(cfg.arena_bytes, 0u, "documented backend default");
	zassert_is_null(cfg.arena, "documented backend default (use heap)");
}

ZTEST(alp_peripheral, test_mbox_config_default)
{
	alp_mbox_config_t cfg = ALP_MBOX_CONFIG_DEFAULT(3u);
	zassert_equal(cfg.channel, 3u, NULL);
	zassert_equal(cfg.peer,
	              ALP_CORE_SELF,
	              "sentinel -- backend routes by channel; set peer to document topology");
}

ZTEST(alp_peripheral, test_shmem_config_default)
{
	alp_shmem_config_t cfg = ALP_SHMEM_CONFIG_DEFAULT("alp_shmem0");
	zassert_str_equal(cfg.name, "alp_shmem0", NULL);
	zassert_equal(
	    cfg.size, 0u, "advisory -- backend derives extent from DT; set size to document intent");
}

ZTEST(alp_peripheral, test_mqtt_config_default)
{
	alp_mqtt_config_t cfg = ALP_MQTT_CONFIG_DEFAULT("mqtt://broker.local:1883");
	zassert_str_equal(cfg.broker_uri, "mqtt://broker.local:1883", NULL);
	zassert_is_null(cfg.client_id, NULL);
	zassert_is_null(cfg.username, NULL);
	zassert_is_null(cfg.password, NULL);
	zassert_equal(cfg.keepalive_s, 60u, "conventional MQTT keepalive");
	zassert_true(cfg.clean_session, NULL);
	zassert_is_null(cfg.tls, "NULL = OS default CA path, no client cert, verify peer");
}

ZTEST(alp_peripheral, test_pwm_capture_config_default)
{
	alp_pwm_capture_config_t cfg = ALP_PWM_CAPTURE_CONFIG_DEFAULT(4u);
	zassert_equal(cfg.channel_id, 4u, NULL);
	zassert_equal(cfg.edge, ALP_PWM_CAPTURE_EDGE_RISING, NULL);
}

ZTEST(alp_peripheral, test_qenc_config_default)
{
	alp_qenc_config_t cfg = ALP_QENC_CONFIG_DEFAULT(1u);
	zassert_equal(cfg.encoder_id, 1u, NULL);
	zassert_equal(cfg.pulses_per_rev, 0u, "informational-only; 0 = unspecified");
}

ZTEST(alp_peripheral, test_rpc_config_default)
{
	alp_rpc_config_t cfg = ALP_RPC_CONFIG_DEFAULT("alp_default_rpmsg");
	zassert_str_equal(cfg.name, "alp_default_rpmsg", NULL);
	zassert_equal(cfg.src_ept, 0u, "0 = FNV-1a hash of name");
	zassert_equal(cfg.dst_ept, 0u, "0 = src_ept + 1");
	zassert_equal(cfg.mbox_ch, ALP_RPC_DEFAULT_MBOX_CH, NULL);
}

ZTEST(alp_peripheral, test_storage_config_default)
{
	alp_storage_config_t cfg = ALP_STORAGE_CONFIG_DEFAULT(ALP_STORAGE_KIND_QSPI_FLASH);
	zassert_equal(cfg.kind, ALP_STORAGE_KIND_QSPI_FLASH, NULL);
	zassert_equal(cfg.instance_id, 0u, "primary device");
	zassert_equal(cfg.freq_hz, 0u, "0 = backend default");
	zassert_false(cfg.read_only, "common writable case");
	/* The SAFE default, and the only thing pinning it.  The Yocto backend
	 * resolves whole-disk /dev/mmcblk<N> and raw /dev/mtd<N> nodes, so a
	 * caller using this macro verbatim must not be able to write or erase
	 * -- offset 0 there is the partition table and the bootloader.  If
	 * this flips to true, that protection is gone repo-wide and nothing
	 * else would notice (#1140). */
	zassert_false(cfg.allow_unsafe_write, "safe default -- see <alp/storage.h>");
}

ZTEST(alp_peripheral, test_usb_device_config_default)
{
	alp_usb_device_config_t cfg = ALP_USB_DEVICE_CONFIG_DEFAULT(ALP_USB_DEVICE_CDC_ACM);
	zassert_equal(cfg.device_class, ALP_USB_DEVICE_CDC_ACM, NULL);
	zassert_equal(cfg.vendor_id, 0x0000u, "placeholder -- caller MUST set before shipping");
	zassert_equal(cfg.product_id, 0x0000u, "placeholder -- caller MUST set before shipping");
	zassert_equal(cfg.bcd_device, 0x0100u, "conventional v1.00 encoding");
	zassert_is_null(cfg.manufacturer, NULL);
	zassert_is_null(cfg.product, NULL);
	zassert_is_null(cfg.serial, NULL);
}
```

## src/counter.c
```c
/*
 * Copyright 2026 Alp Lab AB
 * SPDX-License-Identifier: Apache-2.0
 *
 * <alp/counter.h> -- counter wrapper tests.  §C.16 split + §C.22
 * thin-spot fills: every public function on the counter surface
 * gets a NULL-handle / NULL-arg guard test so the binding-layer
 * contract is exercised on every native_sim build.
 */

#include <zephyr/ztest.h>

#include "alp/counter.h"
#include "alp/peripheral.h"

ZTEST(alp_peripheral, test_counter_null_cfg)
{
	zassert_is_null(alp_counter_open(NULL));
	zassert_equal(alp_last_error(), ALP_ERR_INVAL);
}

/*
 * The alp-sdk#1242 invariant: a PUBLISHED E1M-X connector identity this
 * board does not serve never reports ALP_ERR_INVAL.  INVAL reads as "you
 * passed something malformed" and sends the caller hunting a bug in
 * their own code, when the truth is that this SoM serves fewer counters.
 *
 * Which non-INVAL status appears is deliberately NOT asserted, because it
 * is backend-dependent and both answers are correct:
 *   - with the V2N/V2M supervisor built in, the GD32 bridge is selected
 *     and reports ALP_ERR_NOSUPPORT (it serves ALP_E1M_X_COUNTER0 only);
 *   - otherwise the generic Zephyr backend is selected, whose
 *     `alp-counter<N>` table is a fixed four entries, so a published id
 *     with no alias reports ALP_ERR_NOT_READY.
 * Pinning either one would make this test pass in one twister scenario
 * and fail in the other, which is how it was first written and caught.
 */
ZTEST(alp_peripheral, test_counter_unserved_published_id_is_never_inval)
{
	const alp_counter_config_t cfg = { .counter_id = 3u };

	zassert_is_null(alp_counter_open(&cfg));
	zassert_not_equal(
	    alp_last_error(), ALP_ERR_INVAL, "a published connector id must not report INVAL");
	zassert_true(alp_last_error() == ALP_ERR_NOSUPPORT || alp_last_error() == ALP_ERR_NOT_READY,
	             "expected NOSUPPORT (bridge) or NOT_READY (zephyr), got %d",
	             (int)alp_last_error());
}

ZTEST(alp_peripheral, test_counter_start_null_handle_not_ready)
{
	zassert_equal(alp_counter_start(NULL), ALP_ERR_NOT_READY);
}

ZTEST(alp_peripheral, test_counter_stop_null_handle_not_ready)
{
	zassert_equal(alp_counter_stop(NULL), ALP_ERR_NOT_READY);
}

ZTEST(alp_peripheral, test_counter_get_value_null_handle_not_ready)
{
	uint32_t ticks = 99u;
	zassert_equal(alp_counter_get_value(NULL, &ticks), ALP_ERR_NOT_READY);
}

ZTEST(alp_peripheral, test_counter_get_value_null_out_invalid)
{
	/* NULL out-param is INVAL even when handle is NULL -- the
     * argument-validation pass runs before the handle check. */
	zassert_equal(alp_counter_get_value(NULL, NULL), ALP_ERR_INVAL);
}

ZTEST(alp_peripheral, test_counter_us_to_ticks_null_handle_not_ready)
{
	uint32_t ticks = 99u;
	zassert_equal(alp_counter_us_to_ticks(NULL, 1000u, &ticks), ALP_ERR_NOT_READY);
}

ZTEST(alp_peripheral, test_counter_cancel_alarm_null_handle_not_ready)
{
	zassert_equal(alp_counter_cancel_alarm(NULL), ALP_ERR_NOT_READY);
}

ZTEST(alp_peripheral, test_counter_close_null_is_noop)
{
	/* close(NULL) is a documented no-op; the test just guards
     * against regressions that crash on NULL. */
	alp_counter_close(NULL);
}
```

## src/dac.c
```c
/*
 * Copyright 2026 Alp Lab AB
 * SPDX-License-Identifier: Apache-2.0
 *
 * <alp/peripheral.h> -- DAC wrapper tests.  Extracted from main.c in
 * §C.16.  Covers NULL-cfg INVAL, out-of-range channel, and the
 * NOT_READY-or-NOSUPPORT path when no underlying DAC controller or
 * V2N supervisor is wired.
 */

#include <string.h>

#include <zephyr/ztest.h>

#include "alp/backend.h"                                  /* alp_backend_select / alp_backend_t */
#include "../../../../chips/gd32_swd/gd32_swd_platform.h" /* gd32_swd_session_notify */
#include "alp/dac.h" /* alp_dac_open / alp_dac_t / alp_dac_config_t */
#include "alp/peripheral.h"
#include "alp/soc_caps.h" /* ALP_SOC_DAC_COUNT / ALP_SOC_REF_STR */

ZTEST(alp_peripheral, test_dac_null_cfg)
{
	zassert_is_null(alp_dac_open(NULL));
	zassert_equal(alp_last_error(), ALP_ERR_INVAL);
}

ZTEST(alp_peripheral, test_dac_out_of_range_channel)
{
	/* Channel id 9 is out of range for any E1M part (ALP_E1M_DAC_COUNT = 2).
	 *
	 * Admission is the backend registry, not the SoC cap table (issue
	 * #1642's dispatch-level `ALP_SOC_DAC_COUNT > 0` gate is gone): a
	 * bridged backend on a SoC with ALP_SOC_DAC_COUNT == 0 can still
	 * serve a channel, so alp_dac_open() no longer rejects up front on
	 * the cap table.  Which backend wins (zephyr_drv here, CONFIG_DAC=n
	 * in this suite) decides the code -- NOSUPPORT if the backend
	 * declines outright, INVAL if it bounds-checks the channel itself.
	 * Either way the channel is out of range and open() returns NULL. */
	alp_dac_t *d = alp_dac_open(&(alp_dac_config_t){
	    .channel_id = 9u,
	    .initial_mv = 0u,
	});
	zassert_is_null(d);
}

ZTEST(alp_peripheral, test_dac_unresolved_channel_yields_not_ready)
{
	/* Without a real DAC controller or V2N supervisor backing
     * channel 0, open must fail with NOT_READY (DT-alias path) or
     * NOSUPPORT (CONFIG_DAC=n).  Either is acceptable; both surface
     * as a NULL return. */
	alp_dac_t *d = alp_dac_open(&(alp_dac_config_t){
	    .channel_id = 0u,
	    .initial_mv = 0u,
	});
	zassert_is_null(d);
}

#if defined(CONFIG_ALP_SDK_V2N_SUPERVISOR)
/* Regression pin for issue #1642: on renesas:rzv2n:n44 (this scenario's
 * SoC choice), ALP_SOC_DAC_COUNT == 0 -- the SoC has no on-die DAC -- yet
 * src/backends/dac/gd32_bridge.c registers an EXACT silicon_ref match
 * that serves channels 0/1 over the GD32 bridge.  The deleted dispatch-
 * level `ALP_SOC_DAC_COUNT > 0` gate never actually blocked this case
 * (it was skipped whenever the count was 0), but it stood for the wrong
 * reason and the naive "fix" of flipping the test (reject when count ==
 * 0) would have broken exactly this bridged-channel case.  Prove
 * admission is the registry: a channel gd32_bridge actually serves
 * reaches ITS open() and fails for the real hardware reason (no bus
 * configured -> supervisor NOT_READY), not a cap-table refusal. */
ZTEST(alp_peripheral, test_dac_bridged_channel_admitted_despite_zero_soc_count)
{
	zassert_equal(ALP_SOC_DAC_COUNT, 0, "scenario expects a 0-DAC SoC (renesas:rzv2n:n44)");

	const alp_backend_t *be = alp_backend_select("dac", ALP_SOC_REF_STR);
	zassert_not_null(be, "registry must admit despite ALP_SOC_DAC_COUNT == 0");
	zassert_equal(
	    strcmp(be->vendor, "renesas"), 0, "expected gd32_bridge, got vendor=%s", be->vendor);

	/* channel_id 0 is within gd32_bridge's served range (0/1) even
     * though the SoC cap table says the class has zero instances. */
	alp_dac_t *d = alp_dac_open(&(alp_dac_config_t){
	    .channel_id = 0u,
	    .initial_mv = 0u,
	});
	zassert_is_null(d);
	zassert_equal(alp_last_error(),
	              ALP_ERR_NOT_READY,
	              "channel within the bridge's range must reach gd32_bridge's open() "
	              "(supervisor NOT_READY), not a cap-table refusal");
}

/* While an SWD session owns the GD32 pads (P70/P71/P74 -- P71 is also the
 * bridge ATTN line) every bridge command must answer BUSY and nothing may
 * re-initialise the link; when the session ends the supervisor goes back to
 * its normal behaviour (here: no bus configured -> NOT_READY). */
ZTEST(alp_peripheral, test_v2n_supervisor_answers_busy_during_an_swd_session)
{
	gd32_swd_session_notify(true);
	alp_dac_t *d = alp_dac_open(&(alp_dac_config_t){ .channel_id = 0u, .initial_mv = 0u });
	zassert_is_null(d);
	zassert_equal(alp_last_error(), ALP_ERR_BUSY, "bridge command during an SWD session");

	gd32_swd_session_notify(false);
	d = alp_dac_open(&(alp_dac_config_t){ .channel_id = 0u, .initial_mv = 0u });
	zassert_is_null(d);
	zassert_equal(alp_last_error(), ALP_ERR_NOT_READY, "session over: normal path again");
}
#endif /* CONFIG_ALP_SDK_V2N_SUPERVISOR */
```

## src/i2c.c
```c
/*
 * Copyright 2026 Alp Lab AB
 * SPDX-License-Identifier: Apache-2.0
 *
 * <alp/peripheral.h> -- I2C binding-layer smoke tests.  Extracted from
 * main.c in §C.16 (per-peripheral split).  Coverage focus is the
 * open/close lifecycle + NULL-arg validation + status-code
 * propagation on the Zephyr native_sim backend.
 */

#include <zephyr/ztest.h>

#include "alp/peripheral.h"

ZTEST(alp_peripheral, test_i2c_open_close_roundtrip)
{
	alp_i2c_t *bus = alp_i2c_open(&(alp_i2c_config_t){
	    .bus_id     = 0,
	    .bitrate_hz = 100000,
	});
	zassert_not_null(bus, "alp_i2c_open should succeed for bus_id=0");
	alp_i2c_close(bus);
}

ZTEST(alp_peripheral, test_i2c_open_invalid_bus_returns_null)
{
	alp_i2c_t *bus = alp_i2c_open(&(alp_i2c_config_t){
	    .bus_id     = 99,
	    .bitrate_hz = 100000,
	});
	zassert_is_null(bus, "out-of-range bus_id must yield NULL");
}

ZTEST(alp_peripheral, test_i2c_null_cfg_returns_null)
{
	zassert_is_null(alp_i2c_open(NULL), "NULL cfg must yield NULL");
}

ZTEST(alp_peripheral, test_i2c_write_on_closed_handle_errors)
{
	/* Calling on a NULL handle is the closest portable analogue of
     * "use-after-close" without leaking pool internals. */
	alp_status_t s = alp_i2c_write(NULL, 0x42, (uint8_t[]){ 0xaa }, 1);
	zassert_equal(s, ALP_ERR_NOT_READY, "got %d", (int)s);
}
```
